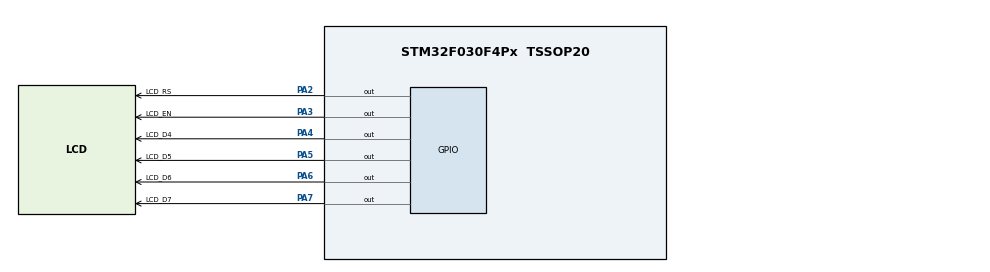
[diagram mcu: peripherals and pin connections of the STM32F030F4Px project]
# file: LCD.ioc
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Mcu.Family=STM32F0
Mcu.Name=STM32F030F4Px
Mcu.Package=TSSOP20
PA13.Mode=Serial_Wire
PA13.Signal=SYS_SWDIO
PA14.Mode=Serial_Wire
PA14.Signal=SYS_SWCLK
PA2.GPIO_Label=LCD_RS
PA2.Signal=GPIO_Output
PA3.GPIO_Label=LCD_EN
PA3.Signal=GPIO_Output
PA4.GPIO_Label=LCD_D4
PA4.Signal=GPIO_Output
PA5.GPIO_Label=LCD_D5
PA5.Signal=GPIO_Output
PA6.GPIO_Label=LCD_D6
PA6.Signal=GPIO_Output
PA7.GPIO_Label=LCD_D7
PA7.Signal=GPIO_Output
PF0-OSC_IN.Mode=HSE-External-Oscillator
PF0-OSC_IN.Signal=RCC_OSC_IN
PF1-OSC_OUT.Mode=HSE-External-Oscillator
PF1-OSC_OUT.Signal=RCC_OSC_OUT
ProjectManager.HeapSize=0x200
ProjectManager.StackSize=0x400
ProjectManager.TargetToolchain=STM32CubeIDE
RCC.PLLSourceVirtual=RCC_PLLSOURCE_HSE
RCC.SYSCLKSource=RCC_SYSCLKSOURCE_HSE
board=custom

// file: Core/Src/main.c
/* USER CODE BEGIN Header */
/**
  ******************************************************************************
  * @file           : main.c
  * @brief          : Main program body
  ******************************************************************************
  * @attention
  *
  * Copyright (c) 2022 STMicroelectronics.
  * All rights reserved.
  *
  * This software is licensed under terms that can be found in the LICENSE file
  * in the root directory of this software component.
  * If no LICENSE file comes with this software, it is provided AS-IS.
  *
  ******************************************************************************
  */
/* USER CODE END Header */
#include "main.h"

/* USER CODE BEGIN Includes */
#include "lcd.h"
/* USER CODE END Includes */

void SystemClock_Config(void);
static void MX_GPIO_Init(void);

int main(void)
{

  /* MCU Configuration--------------------------------------------------------*/

  /* Reset of all peripherals, Initializes the Flash interface and the Systick. */
  HAL_Init();

  /* Configure the system clock */
  SystemClock_Config();

  /* Initialize all configured peripherals */
  MX_GPIO_Init();
  /* USER CODE BEGIN 2 */
  lcdInit(_LCD_4BIT,_LCD_FONT_5x8,_LCD_2LINE);
  lcdClear();
  lcdPrint(1,1,"ONUR BiLKE");
  lcdPrint(2,1,"STM32 EXAMPLES");
  /* USER CODE END 2 */

  /* Infinite loop */
  while (1)
  {

  }
}

void SystemClock_Config(void)
{
  RCC_OscInitTypeDef RCC_OscInitStruct = {0};
  RCC_ClkInitTypeDef RCC_ClkInitStruct = {0};

  /** Initializes the RCC Oscillators according to the specified parameters
  * in the RCC_OscInitTypeDef structure.
  */
  RCC_OscInitStruct.OscillatorType = RCC_OSCILLATORTYPE_HSE;
  RCC_OscInitStruct.HSEState = RCC_HSE_ON;
  RCC_OscInitStruct.PLL.PLLState = RCC_PLL_NONE;
  if (HAL_RCC_OscConfig(&RCC_OscInitStruct) != HAL_OK)
  {
    Error_Handler();
  }

  /** Initializes the CPU, AHB and APB buses clocks
  */
  RCC_ClkInitStruct.ClockType = RCC_CLOCKTYPE_HCLK|RCC_CLOCKTYPE_SYSCLK
                              |RCC_CLOCKTYPE_PCLK1;
  RCC_ClkInitStruct.SYSCLKSource = RCC_SYSCLKSOURCE_HSE;
  RCC_ClkInitStruct.AHBCLKDivider = RCC_SYSCLK_DIV1;
  RCC_ClkInitStruct.APB1CLKDivider = RCC_HCLK_DIV1;

  if (HAL_RCC_ClockConfig(&RCC_ClkInitStruct, FLASH_LATENCY_0) != HAL_OK)
  {
    Error_Handler();
  }
}

static void MX_GPIO_Init(void)
{
  GPIO_InitTypeDef GPIO_InitStruct = {0};

  /* GPIO Ports Clock Enable */
  __HAL_RCC_GPIOF_CLK_ENABLE();
  __HAL_RCC_GPIOA_CLK_ENABLE();

  /*Configure GPIO pin Output Level */
  HAL_GPIO_WritePin(GPIOA, LCD_RS_Pin|LCD_EN_Pin|LCD_D4_Pin|LCD_D5_Pin
                          |LCD_D6_Pin|LCD_D7_Pin, GPIO_PIN_RESET);

  /*Configure GPIO pins : LCD_RS_Pin LCD_EN_Pin LCD_D4_Pin LCD_D5_Pin
                           LCD_D6_Pin LCD_D7_Pin */
  GPIO_InitStruct.Pin = LCD_RS_Pin|LCD_EN_Pin|LCD_D4_Pin|LCD_D5_Pin
                          |LCD_D6_Pin|LCD_D7_Pin;
  GPIO_InitStruct.Mode = GPIO_MODE_OUTPUT_PP;
  GPIO_InitStruct.Pull = GPIO_NOPULL;
  GPIO_InitStruct.Speed = GPIO_SPEED_FREQ_LOW;
  HAL_GPIO_Init(GPIOA, &GPIO_InitStruct);

}

void Error_Handler(void)
{
  __disable_irq();
  while (1)
  {
  }
}
